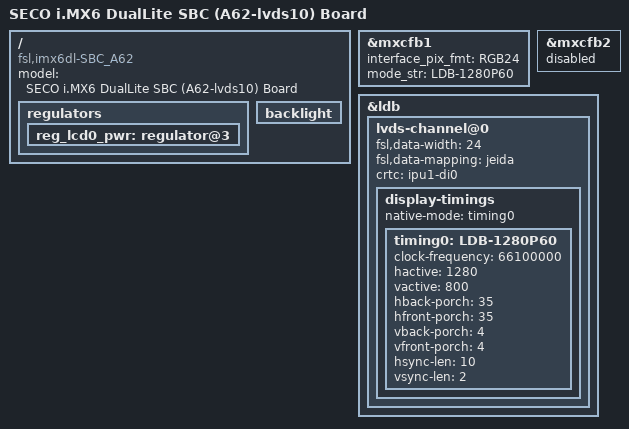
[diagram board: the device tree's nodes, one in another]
/*
 * Copyright 2013 Freescale Semiconductor, Inc.
 * Copyright 2015 Aidilab, Srl.
 *
 * The code contained herein is licensed under the GNU General Public
 * License. You may obtain a copy of the GNU General Public License
 * Version 2 or later at the following locations:
 *
 * http://www.opensource.org/licenses/gpl-license.html
 * http://www.gnu.org/copyleft/gpl.html
 */

/dts-v1/;

#include "imx6dl.dtsi"
#include "imx6qdl-seco_A62.dtsi"

/ {
	model = "SECO i.MX6 DualLite SBC (A62-lvds10) Board";
	compatible = "fsl,imx6dl-SBC_A62", "fsl,imx6dl";

	regulators {
		reg_lcd0_pwr: regulator@3 {
			status = "okay";
		};
	};
	
	backlight {
		status = "okay";
	};
};

&mxcfb1 {
	interface_pix_fmt = "RGB24";
	mode_str ="LDB-1280P60";
	status = "okay";
};

&mxcfb2 {
	status = "disabled";
};

&ldb {
	status = "okay";
	lvds-channel@0 {     
		status = "okay";
		fsl,data-width = <24>;
		fsl,data-mapping = "jeida"; 
		crtc = "ipu1-di0";
		display-timings {
			native-mode = <&timing0>;
			timing0: LDB-1280P60 {
				clock-frequency = <66100000>;
				hactive = <1280>;
				vactive = <800>;
				hback-porch = <35>;
				hfront-porch = <35>;
				vback-porch = <4>;
				vfront-porch = <4>;
				hsync-len = <10>;
				vsync-len = <2>;
			};
		};
	};
};
